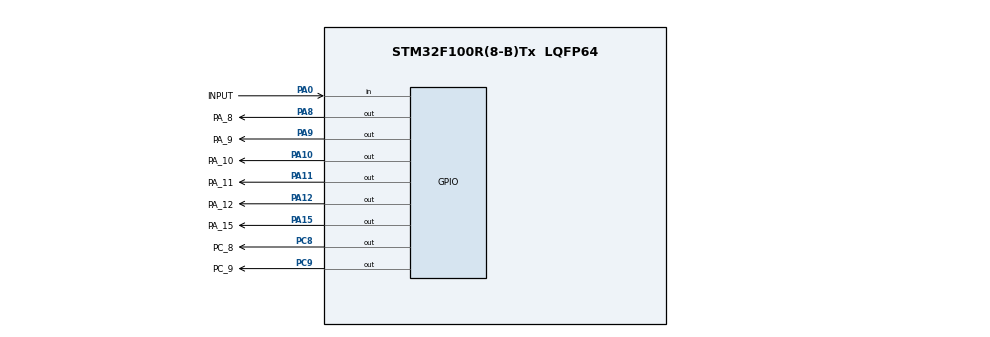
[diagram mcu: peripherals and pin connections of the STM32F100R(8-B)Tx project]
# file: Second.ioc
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Mcu.Family=STM32F1
Mcu.Name=STM32F100R(8-B)Tx
Mcu.Package=LQFP64
NVIC.PriorityGroup=NVIC_PRIORITYGROUP_4
PA0-WKUP.GPIO_Label=INPUT
PA0-WKUP.Signal=GPIO_Input
PA10.GPIO_Label=PA_10
PA10.Signal=GPIO_Output
PA11.GPIO_Label=PA_11
PA11.Signal=GPIO_Output
PA12.GPIO_Label=PA_12
PA12.Signal=GPIO_Output
PA13.Mode=Serial_Wire
PA13.Signal=SYS_JTMS-SWDIO
PA14.Mode=Serial_Wire
PA14.Signal=SYS_JTCK-SWCLK
PA15.GPIO_Label=PA_15
PA15.Signal=GPIO_Output
PA8.GPIO_Label=PA_8
PA8.Signal=GPIO_Output
PA9.GPIO_Label=PA_9
PA9.Signal=GPIO_Output
PC8.GPIO_Label=PC_8
PC8.Signal=GPIO_Output
PC9.GPIO_Label=PC_9
PC9.Signal=GPIO_Output
ProjectManager.HeapSize=0x200
ProjectManager.StackSize=0x400
ProjectManager.TargetToolchain=STM32CubeIDE
RCC.APB1Freq_Value=8000000
RCC.APB2Freq_Value=8000000
board=custom

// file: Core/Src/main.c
/* USER CODE BEGIN Header */
/**
  ******************************************************************************
  * @file           : main.c
  * @brief          : Main program body
  ******************************************************************************
  * @attention
  *
  * Copyright (c) 2022 STMicroelectronics.
  * All rights reserved.
  *
  * This software is licensed under terms that can be found in the LICENSE file
  * in the root directory of this software component.
  * If no LICENSE file comes with this software, it is provided AS-IS.
  *
  ******************************************************************************
  */
/* USER CODE END Header */
#include "main.h"

/* USER CODE BEGIN Includes */
int A,B;
/* USER CODE END Includes */

void SystemClock_Config(void);
static void MX_GPIO_Init(void);

int main(void)
{

  /* MCU Configuration--------------------------------------------------------*/

  /* Reset of all peripherals, Initializes the Flash interface and the Systick. */
  HAL_Init();

  /* Configure the system clock */
  SystemClock_Config();

  /* Initialize all configured peripherals */
  MX_GPIO_Init();

  /* Infinite loop */
  /* USER CODE BEGIN WHILE */
  while (1)
  {
	  /*HAL_GPIO_WritePin(PA_10_GPIO_Port, PA_10_Pin, GPIO_PIN_SET);
	  	 HAL_Delay(500);

     HAL_GPIO_WritePin(PA_10_GPIO_Port, PA_10_Pin, GPIO_PIN_RESET);

	 HAL_GPIO_WritePin(PA_11_GPIO_Port, PA_11_Pin, GPIO_PIN_SET);
	    HAL_Delay(500);

	 HAL_GPIO_WritePin(PA_11_GPIO_Port, PA_11_Pin, GPIO_PIN_RESET);

	 HAL_GPIO_WritePin(PC_9_GPIO_Port, PC_9_Pin, GPIO_PIN_SET);
	    HAL_Delay(500);

	 HAL_GPIO_WritePin(PC_9_GPIO_Port, PC_9_Pin, GPIO_PIN_RESET);

	 HAL_GPIO_WritePin(PC_8_GPIO_Port, PC_8_Pin, GPIO_PIN_SET);
		 HAL_Delay(500);

     HAL_GPIO_WritePin(PC_8_GPIO_Port, PC_8_Pin, GPIO_PIN_RESET);

     HAL_GPIO_WritePin(PA_15_GPIO_Port, PA_15_Pin, GPIO_PIN_SET);
    	  HAL_Delay(500);

     HAL_GPIO_WritePin(PA_15_GPIO_Port, PA_15_Pin, GPIO_PIN_RESET);

     HAL_GPIO_WritePin(PA_12_GPIO_Port, PA_12_Pin, GPIO_PIN_SET);
    	  HAL_Delay(500);

     HAL_GPIO_WritePin(PA_12_GPIO_Port, PA_12_Pin, GPIO_PIN_RESET);*/

     /*if( HAL_GPIO_ReadPin(INPUT_GPIO_Port, INPUT_Pin) == 1)
    	  {
    		  HAL_GPIO_WritePin(PA_8_GPIO_Port, PA_8_Pin, GPIO_PIN_RESET);
    	  }
    	  else
    	  {
    		  HAL_GPIO_WritePin(PA_8_GPIO_Port, PA_8_Pin, GPIO_PIN_SET);

    	  }

     if( HAL_GPIO_ReadPin(INPUT_GPIO_Port, INPUT_Pin) == 1)
          {
         	  HAL_GPIO_WritePin(PA_9_GPIO_Port, PA_9_Pin, GPIO_PIN_SET);
          }
          else
          {
         	  HAL_GPIO_WritePin(PA_9_GPIO_Port, PA_9_Pin, GPIO_PIN_RESET);

          }

     if( HAL_GPIO_ReadPin(INPUT_GPIO_Port, INPUT_Pin) == 1)
        	  {
        		  HAL_GPIO_WritePin(PA_10_GPIO_Port, PA_10_Pin, GPIO_PIN_RESET);
        	  }
        	  else
        	  {
        		  HAL_GPIO_WritePin(PA_10_GPIO_Port, PA_10_Pin, GPIO_PIN_SET);

        	  }

         if( HAL_GPIO_ReadPin(INPUT_GPIO_Port, INPUT_Pin) == 1)
              {
             	  HAL_GPIO_WritePin(PA_11_GPIO_Port, PA_11_Pin, GPIO_PIN_SET);
              }
              else
              {
             	  HAL_GPIO_WritePin(PA_11_GPIO_Port, PA_11_Pin, GPIO_PIN_RESET);

              }

         if( HAL_GPIO_ReadPin(INPUT_GPIO_Port, INPUT_Pin) == 1)
              {
                  HAL_GPIO_WritePin(PA_12_GPIO_Port, PA_12_Pin, GPIO_PIN_RESET);
              }
                else
              {
                  HAL_GPIO_WritePin(PA_12_GPIO_Port, PA_12_Pin, GPIO_PIN_SET);

              }

         if( HAL_GPIO_ReadPin(INPUT_GPIO_Port, INPUT_Pin) == 1)
              {
                 HAL_GPIO_WritePin(PA_15_GPIO_Port, PA_15_Pin, GPIO_PIN_SET);
               }
                 else
               {
              	  HAL_GPIO_WritePin(PA_15_GPIO_Port, PA_15_Pin, GPIO_PIN_RESET);

               }

         if( HAL_GPIO_ReadPin(INPUT_GPIO_Port, INPUT_Pin) == 1)
            	  {
            		  HAL_GPIO_WritePin(PC_8_GPIO_Port, PC_8_Pin, GPIO_PIN_RESET);
            	  }
            	  else
            	  {
            		  HAL_GPIO_WritePin(PC_8_GPIO_Port, PC_8_Pin, GPIO_PIN_SET);

            	  }

        if( HAL_GPIO_ReadPin(INPUT_GPIO_Port, INPUT_Pin) == 1)
              {
                 HAL_GPIO_WritePin(PC_9_GPIO_Port, PC_9_Pin, GPIO_PIN_SET);
              }
              else
              {
                 HAL_GPIO_WritePin(PC_9_GPIO_Port, PC_9_Pin, GPIO_PIN_RESET);*/

	  HAL_GPIO_WritePin(PA_10_GPIO_Port, PA_10_Pin, GPIO_PIN_SET);
	  	  	 HAL_Delay(500);

	       HAL_GPIO_WritePin(PA_10_GPIO_Port, PA_10_Pin, GPIO_PIN_RESET);

	  	 HAL_GPIO_WritePin(PA_11_GPIO_Port, PA_11_Pin, GPIO_PIN_SET);
	  	    HAL_Delay(500);

	  	 HAL_GPIO_WritePin(PA_11_GPIO_Port, PA_11_Pin, GPIO_PIN_RESET);

	  	 if( HAL_GPIO_ReadPin(INPUT_GPIO_Port, INPUT_Pin) == 1)
	  	         {
	  	          HAL_GPIO_WritePin(PA_11_GPIO_Port, PA_11_Pin, GPIO_PIN_SET);
	  	        HAL_Delay(5000);
	  	         }
	  	         else
	  	         {
	  	           HAL_GPIO_WritePin(PA_11_GPIO_Port, PA_11_Pin, GPIO_PIN_RESET);

	  	         }
              }
    /* USER CODE END WHILE */

  }

void SystemClock_Config(void)
{
  RCC_OscInitTypeDef RCC_OscInitStruct = {0};
  RCC_ClkInitTypeDef RCC_ClkInitStruct = {0};

  /** Initializes the RCC Oscillators according to the specified parameters
  * in the RCC_OscInitTypeDef structure.
  */
  RCC_OscInitStruct.OscillatorType = RCC_OSCILLATORTYPE_HSI;
  RCC_OscInitStruct.HSIState = RCC_HSI_ON;
  RCC_OscInitStruct.HSICalibrationValue = RCC_HSICALIBRATION_DEFAULT;
  RCC_OscInitStruct.PLL.PLLState = RCC_PLL_NONE;
  if (HAL_RCC_OscConfig(&RCC_OscInitStruct) != HAL_OK)
  {
    Error_Handler();
  }

  /** Initializes the CPU, AHB and APB buses clocks
  */
  RCC_ClkInitStruct.ClockType = RCC_CLOCKTYPE_HCLK|RCC_CLOCKTYPE_SYSCLK
                              |RCC_CLOCKTYPE_PCLK1|RCC_CLOCKTYPE_PCLK2;
  RCC_ClkInitStruct.SYSCLKSource = RCC_SYSCLKSOURCE_HSI;
  RCC_ClkInitStruct.AHBCLKDivider = RCC_SYSCLK_DIV1;
  RCC_ClkInitStruct.APB1CLKDivider = RCC_HCLK_DIV1;
  RCC_ClkInitStruct.APB2CLKDivider = RCC_HCLK_DIV1;

  if (HAL_RCC_ClockConfig(&RCC_ClkInitStruct, FLASH_LATENCY_0) != HAL_OK)
  {
    Error_Handler();
  }
}

static void MX_GPIO_Init(void)
{
  GPIO_InitTypeDef GPIO_InitStruct = {0};

  /* GPIO Ports Clock Enable */
  __HAL_RCC_GPIOA_CLK_ENABLE();
  __HAL_RCC_GPIOC_CLK_ENABLE();

  /*Configure GPIO pin Output Level */
  HAL_GPIO_WritePin(GPIOC, PC_8_Pin|PC_9_Pin, GPIO_PIN_RESET);

  /*Configure GPIO pin Output Level */
  HAL_GPIO_WritePin(GPIOA, PA_8_Pin|PA_9_Pin|PA_10_Pin|PA_11_Pin
                          |PA_12_Pin|PA_15_Pin, GPIO_PIN_RESET);

  /*Configure GPIO pin : INPUT_Pin */
  GPIO_InitStruct.Pin = INPUT_Pin;
  GPIO_InitStruct.Mode = GPIO_MODE_INPUT;
  GPIO_InitStruct.Pull = GPIO_NOPULL;
  HAL_GPIO_Init(INPUT_GPIO_Port, &GPIO_InitStruct);

  /*Configure GPIO pins : PC_8_Pin PC_9_Pin */
  GPIO_InitStruct.Pin = PC_8_Pin|PC_9_Pin;
  GPIO_InitStruct.Mode = GPIO_MODE_OUTPUT_PP;
  GPIO_InitStruct.Pull = GPIO_NOPULL;
  GPIO_InitStruct.Speed = GPIO_SPEED_FREQ_LOW;
  HAL_GPIO_Init(GPIOC, &GPIO_InitStruct);

  /*Configure GPIO pins : PA_8_Pin PA_9_Pin PA_10_Pin PA_11_Pin
                           PA_12_Pin PA_15_Pin */
  GPIO_InitStruct.Pin = PA_8_Pin|PA_9_Pin|PA_10_Pin|PA_11_Pin
                          |PA_12_Pin|PA_15_Pin;
  GPIO_InitStruct.Mode = GPIO_MODE_OUTPUT_PP;
  GPIO_InitStruct.Pull = GPIO_NOPULL;
  GPIO_InitStruct.Speed = GPIO_SPEED_FREQ_LOW;
  HAL_GPIO_Init(GPIOA, &GPIO_InitStruct);

}

void Error_Handler(void)
{
  __disable_irq();
  while (1)
  {
  }
}
